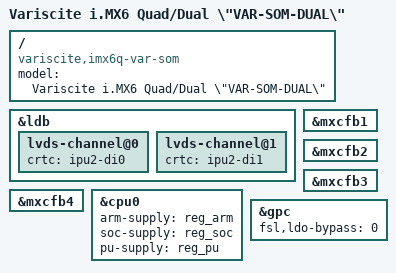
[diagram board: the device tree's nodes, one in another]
/*
 * Copyright (C) 2014-2021 Variscite, Ltd. All Rights Reserved
 *
 * This program is free software; you can redistribute it and/or modify
 * it under the terms of the GNU General Public License version 2 as
 * published by the Free Software Foundation.
 */

/dts-v1/;

#include "imx6q.dtsi"
#include "imx6qdl-var-som.dtsi"

/ {
	model = "Variscite i.MX6 Quad/Dual \"VAR-SOM-DUAL\"";
	compatible = "variscite,imx6q-var-som", "fsl,imx6q";
};

&ldb {
	lvds-channel@0 {
		crtc = "ipu2-di0";
	};

	lvds-channel@1 {
		crtc = "ipu2-di1";
	};
};

&mxcfb1 {
	status = "okay";
};

&mxcfb2 {
	status = "okay";
};

&mxcfb3 {
	status = "okay";
};

&mxcfb4 {
	status = "okay";
};

&cpu0 {
	arm-supply = <&reg_arm>;
	soc-supply = <&reg_soc>;
	pu-supply = <&reg_pu>; /* use pu_dummy if VDDSOC share with VDDPU */
};

&gpc {
	/* use ldo-enable, u-boot will check it and configure */
	fsl,ldo-bypass = <0>;
};
